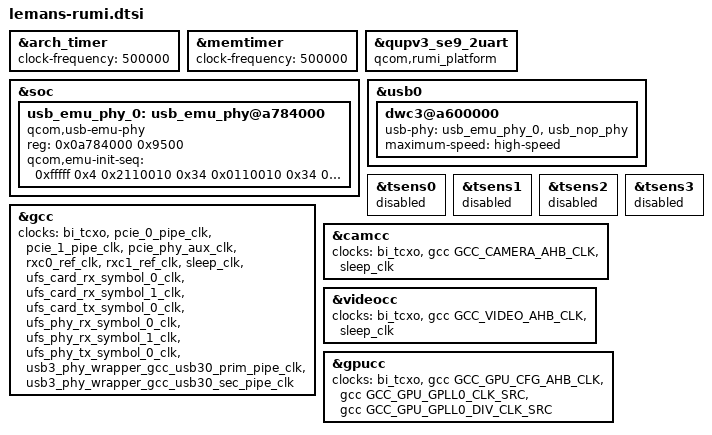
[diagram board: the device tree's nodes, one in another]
#include "lemans.dtsi"
#include <dt-bindings/clock/qcom,gcc-lemans.h>

&arch_timer {
	clock-frequency = <500000>;
};

&memtimer {
	clock-frequency = <500000>;
};

&qupv3_se9_2uart {
	status = "ok";
	qcom,rumi_platform;
};

&soc {
	usb_emu_phy_0: usb_emu_phy@a784000 {
		compatible = "qcom,usb-emu-phy";
		reg = <0x0a784000 0x9500>;

		qcom,emu-init-seq = <0xfffff 0x4
				     0x2110010 0x34
				     0x0110010 0x34
				     0xffff3 0x4
				     0xffff0 0x4
				     0x100000 0x20
				     0x0 0x20
				     0x1A0 0x20
				     0x100000 0x3c
				     0x0 0x3c
				     0x10060 0x3c
				     0x0 0x4
				     0x9 0x14>;
	};
};

&usb0 {
	dwc3@a600000 {
		usb-phy = <&usb_emu_phy_0>, <&usb_nop_phy>;
		maximum-speed = "high-speed";
	};
};

&tsens0 {
		status = "disabled";
};

&tsens1 {
		status = "disabled";
};

&tsens2 {
		status = "disabled";
};

&tsens3 {
		status = "disabled";
};

&gcc {
	clocks = <&bi_tcxo>, <&pcie_0_pipe_clk>, <&pcie_1_pipe_clk>,
		 <&pcie_phy_aux_clk>, <&rxc0_ref_clk>, <&rxc1_ref_clk>,
		 <&sleep_clk>, <&ufs_card_rx_symbol_0_clk>, <&ufs_card_rx_symbol_1_clk>,
		 <&ufs_card_tx_symbol_0_clk>, <&ufs_phy_rx_symbol_0_clk>,
		 <&ufs_phy_rx_symbol_1_clk>, <&ufs_phy_tx_symbol_0_clk>,
		 <&usb3_phy_wrapper_gcc_usb30_prim_pipe_clk>,
		 <&usb3_phy_wrapper_gcc_usb30_sec_pipe_clk>;
};

&camcc {
	clocks = <&bi_tcxo>, <&gcc GCC_CAMERA_AHB_CLK>, <&sleep_clk>;
};

&videocc {
	clocks = <&bi_tcxo>, <&gcc GCC_VIDEO_AHB_CLK>, <&sleep_clk>;
};

&gpucc {
	clocks = <&bi_tcxo>, <&gcc GCC_GPU_CFG_AHB_CLK>,
		 <&gcc GCC_GPU_GPLL0_CLK_SRC>, <&gcc GCC_GPU_GPLL0_DIV_CLK_SRC>;
};
